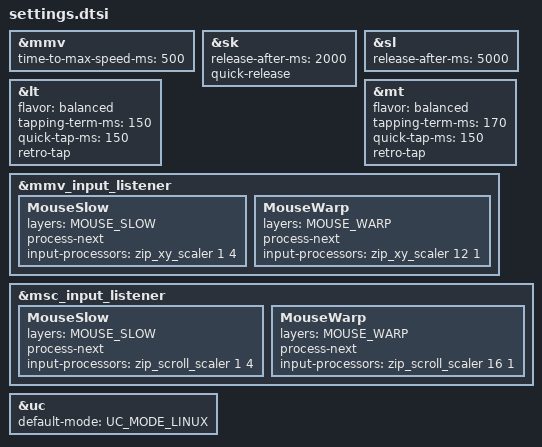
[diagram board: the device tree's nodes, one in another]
&mmv {
	time-to-max-speed-ms = <500>;// Default 300
};

&sk {// sticky-key
	release-after-ms = <2000>;
	quick-release;// no double capitalization when rolling keys
};

&sl {
	release-after-ms = <5000>;
   /* /delete-property/ quick-release; */
};

/* &sl {// sticky-layer  */
	/*     ignore-modifiers;// allow chording sticky mods & layers */
/* }; */

&lt {// layer-tap config
	flavor = "balanced";
	tapping-term-ms = <150>;
	quick-tap-ms = <150>;
	retro-tap;
};

/* &lt {// prófum urob home row stillingarnar */
	/*     flavor = "balanced"; */
	/*     tapping-term-ms = <280>; */
	/*     quick-tap-ms = <175>; */
	/* require-prior-idle-ms = <150>; */
	/*     hold-trigger-on-release; */
/* }; */


&mt {// layer-tap config
	flavor = "balanced";
	tapping-term-ms = <170>;
	quick-tap-ms = <150>;
	retro-tap;
};


&mmv_input_listener {
	MouseSlow {
		layers = <MOUSE_SLOW>;
		process-next;
		input-processors = <&zip_xy_scaler 1 4>;
	};
	MouseWarp {
		layers = <MOUSE_WARP>;
		process-next;
		input-processors = <&zip_xy_scaler 12 1>;
	};
};

&msc_input_listener {
	MouseSlow {
		layers = <MOUSE_SLOW>;
		process-next;
		input-processors = <&zip_scroll_scaler 1 4>;
	};
	MouseWarp {
		layers = <MOUSE_WARP>;
		process-next;
		input-processors = <&zip_scroll_scaler 16 1>;
	};
};

&uc {
  default-mode = <UC_MODE_LINUX>;
};
